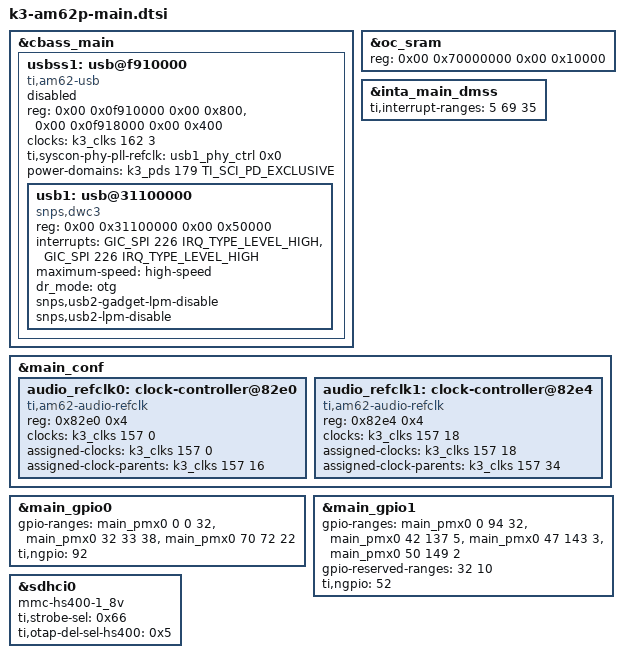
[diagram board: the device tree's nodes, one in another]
// SPDX-License-Identifier: GPL-2.0-only OR MIT
/*
 * Device Tree file for the AM62P MAIN domain peripherals
 *
 * Copyright (C) 2023-2024 Texas Instruments Incorporated - https://www.ti.com/
 */

&cbass_main {
	usbss1: usb@f910000 {
		compatible = "ti,am62-usb";
		reg = <0x00 0x0f910000 0x00 0x800>,
		      <0x00 0x0f918000 0x00 0x400>;
		clocks = <&k3_clks 162 3>;
		clock-names = "ref";
		ti,syscon-phy-pll-refclk = <&usb1_phy_ctrl 0x0>;
		#address-cells = <2>;
		#size-cells = <2>;
		power-domains = <&k3_pds 179 TI_SCI_PD_EXCLUSIVE>;
		ranges;
		status = "disabled";

		usb1: usb@31100000 {
			compatible = "snps,dwc3";
			reg = <0x00 0x31100000 0x00 0x50000>;
			interrupts = <GIC_SPI 226 IRQ_TYPE_LEVEL_HIGH>, /* irq.0 */
			<GIC_SPI 226 IRQ_TYPE_LEVEL_HIGH>; /* irq.0 */
			interrupt-names = "host", "peripheral";
			maximum-speed = "high-speed";
			dr_mode = "otg";
			snps,usb2-gadget-lpm-disable;
			snps,usb2-lpm-disable;
		};
	};
};

&oc_sram {
	reg = <0x00 0x70000000 0x00 0x10000>;
	ranges = <0x00 0x00 0x70000000 0x10000>;
};

&inta_main_dmss {
	ti,interrupt-ranges = <5 69 35>;
};

&main_conf {
	audio_refclk0: clock-controller@82e0 {
		compatible = "ti,am62-audio-refclk";
		reg = <0x82e0 0x4>;
		clocks = <&k3_clks 157 0>;
		assigned-clocks = <&k3_clks 157 0>;
		assigned-clock-parents = <&k3_clks 157 16>;
		#clock-cells = <0>;
	};

	audio_refclk1: clock-controller@82e4 {
		compatible = "ti,am62-audio-refclk";
		reg = <0x82e4 0x4>;
		clocks = <&k3_clks 157 18>;
		assigned-clocks = <&k3_clks 157 18>;
		assigned-clock-parents = <&k3_clks 157 34>;
		#clock-cells = <0>;
	};
};

&main_gpio0 {
	gpio-ranges = <&main_pmx0 0 0 32>, <&main_pmx0 32 33 38>,
			<&main_pmx0 70 72 22>;
	ti,ngpio = <92>;
};

&main_gpio1 {
	gpio-ranges = <&main_pmx0 0 94 32>, <&main_pmx0 42 137 5>,
			<&main_pmx0 47 143 3>, <&main_pmx0 50 149 2>;
	gpio-reserved-ranges = <32 10>;
	ti,ngpio = <52>;
};

&sdhci0 {
	mmc-hs400-1_8v;
	ti,strobe-sel = <0x66>;
	ti,otap-del-sel-hs400 = <0x5>;
};
